VERSION "created by canmatrix"

NS_ :

BS_:

BU_:

BO_ 16751425 CommandModeControlAPU2: 9 Vector__XXX
 SG_ Enable_command : 6|2@0+ (1,0) [0|3] "" Vector__XXX
 SG_ FaultClear_command : 4|2@0+ (1,0) [0|3] "" Vector__XXX
 SG_ MasterFollowerMode_command : 22|2@0+ (1,0) [0|3] "" Vector__XXX
 SG_ ForceRelayMX1_command : 38|2@0+ (1,0) [0|3] "" Vector__XXX
 SG_ ForceRelayMX2_command : 36|2@0+ (1,0) [0|3] "" Vector__XXX
 SG_ ForceRelayK1_Precharge_command : 34|2@0+ (1,0) [0|3] "" Vector__XXX
 SG_ ForceRelayRelayK2_DCRun_comand : 32|2@0+ (1,0) [0|3] "" Vector__XXX
 SG_ InvertHwEnable_command : 62|2@0+ (1,0) [0|3] "" Vector__XXX
 SG_ EnableUPSMode_command : 60|2@0+ (1,0) [0|3] "" Vector__XXX
 SG_ EnableSplitPhase_command : 58|2@0+ (1,0) [0|3] "" Vector__XXX
 SG_ PhaseRotation_command : 56|2@0+ (1,0) [0|3] "" Vector__XXX

BO_ 16755521 CommandModeControl: 9 Vector__XXX
 SG_ Enable_command : 6|2@0+ (1,0) [0|3] "" Vector__XXX
 SG_ FaultClear_command : 4|2@0+ (1,0) [0|3] "" Vector__XXX
 SG_ MasterFollowerMode_command : 22|2@0+ (1,0) [0|3] "" Vector__XXX
 SG_ ForceRelayMX1_command : 38|2@0+ (1,0) [0|3] "" Vector__XXX
 SG_ ForceRelayMX2_command : 36|2@0+ (1,0) [0|3] "" Vector__XXX
 SG_ ForceRelayK1_Precharge_command : 34|2@0+ (1,0) [0|3] "" Vector__XXX
 SG_ ForceRelayRelayK2_DCRun_comand : 32|2@0+ (1,0) [0|3] "" Vector__XXX
 SG_ InvertHwEnable_command : 62|2@0+ (1,0) [0|3] "" Vector__XXX
 SG_ EnableUPSMode_command : 60|2@0+ (1,0) [0|3] "" Vector__XXX
 SG_ EnableSplitPhase_command : 58|2@0+ (1,0) [0|3] "" Vector__XXX
 SG_ PhaseRotation_command : 56|2@0+ (1,0) [0|3] "" Vector__XXX

BO_ 218078273 CommandPowerAPU2: 9 Vector__XXX
 SG_ RealPower_command : 0|32@0+ (1,-90000) [-90000|90000] "W" Vector__XXX
 SG_ ReactivePower_command : 32|32@0+ (1,-90000) [-90000|90000] "VA" Vector__XXX

BO_ 218078785 CommandVFAPU2: 8 Vector__XXX
 SG_ Voltage_command : 0|16@0+ (0.1,10) [10|500] "Vrms" Vector__XXX
 SG_ Frequency_command : 16|16@0+ (0.1,45) [45|65] "Hz" Vector__XXX

BO_ 218081857 CommandSetNVParam: 9 Vector__XXX
 SG_ CommandSetNVParam_MUX M : 0|16@0+ (1,0) [0|65535] "" Vector__XXX
 SG_ ThermalOverload m6 : 22|2@0+ (1,0) [0|3] "" Vector__XXX
 SG_ Dummy m0 : 16|16@0+ (1,0) [0|65535] "" Vector__XXX
 SG_ FreqHi0 m3 : 16|16@0+ (0.1,40) [40|70] "Hz" Vector__XXX
 SG_ FreqVeryLo0 m4 : 16|16@0+ (1,160) [160|160] "ms" Vector__XXX
 SG_ K2Open m9 : 16|16@0+ (1,0) [0|2000] "ms" Vector__XXX
 SG_ MX1Open m7 : 16|16@0+ (1,0) [0|5000] "ms" Vector__XXX
 SG_ MX2Close m8 : 16|16@0+ (1,0) [0|2000] "ms" Vector__XXX
 SG_ NodeID m5 : 16|8@0+ (1,0) [0|247] "" Vector__XXX
 SG_ VOver120 m2 : 16|16@0+ (1,1) [1|30000] "" Vector__XXX
 SG_ VUnder50pct m1 : 16|16@0+ (1,1) [1|30000] "ms" Vector__XXX
 SG_ SA_Mask m5 : 24|8@0+ (1,0) [0|255] "" Vector__XXX
 SG_ Baudrate m5 : 32|4@0+ (1,0) [0|15] "" Vector__XXX
 SG_ FreqLo m4 : 32|16@0+ (1,1) [1|30000] "ms" Vector__XXX
 SG_ K1Open m8 : 32|16@0+ (1,0) [0|2000] "ms" Vector__XXX
 SG_ K2Close m9 : 32|16@0+ (1,0) [0|2000] "ms" Vector__XXX
 SG_ MX1Close m7 : 32|16@0+ (1,0) [0|2000] "ms" Vector__XXX
 SG_ V50to88pct m1 : 32|16@0+ (1,1) [1|30000] "ms" Vector__XXX
 SG_ FreqHi1 m4 : 48|16@0+ (1,160) [160|160] "ms" Vector__XXX
 SG_ FreqVeryLo1 m3 : 48|16@0+ (0.1,40) [40|70] "Hz" Vector__XXX
 SG_ K1Close m8 : 48|16@0+ (1,0) [0|2000] "ms" Vector__XXX
 SG_ MX2Open m7 : 48|16@0+ (1,0) [0|65535] "ms" Vector__XXX
 SG_ V110to120pct m1 : 48|16@0+ (1,1) [1|30000] "ms" Vector__XXX

BO_ 218082369 CommandPower: 9 Vector__XXX
 SG_ RealPower_command : 0|32@0+ (1,-90000) [-90000|90000] "W" Vector__XXX
 SG_ ReactivePower_command : 32|32@0+ (1,-90000) [-90000|90000] "VA" Vector__XXX

BO_ 218082881 CommandVF: 8 Vector__XXX
 SG_ Voltage_command : 0|16@0+ (0.1,10) [10|500] "Vrms" Vector__XXX
 SG_ Frequency_command : 16|16@0+ (0.1,45) [45|65] "Hz" Vector__XXX

BO_ 218083137 CommandFactoryControl: 9 Vector__XXX
 SG_ WriteSerialNumber : 6|2@0+ (1,0) [0|3] "" Vector__XXX
 SG_ FactoryAccess : 16|16@0+ (1,0) [0|65535] "" Vector__XXX
 SG_ SerialNumber : 32|32@0+ (1,0) [0|4294967295] "" Vector__XXX

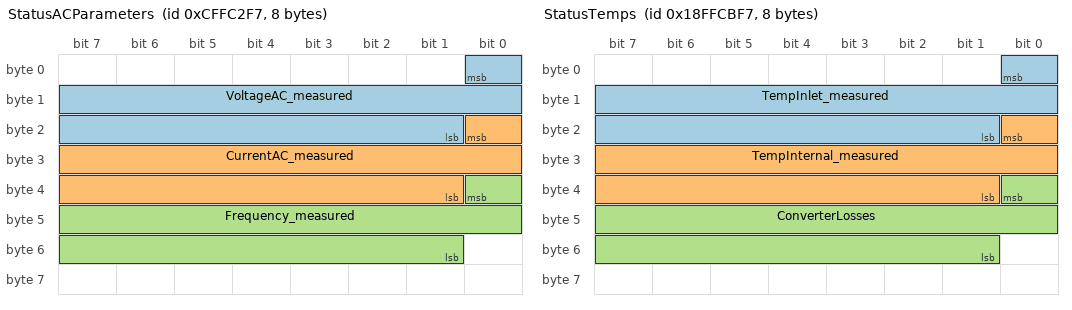
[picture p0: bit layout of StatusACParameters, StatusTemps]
BO_ 218088183 StatusACParameters: 8 Vector__XXX
 SG_ VoltageAC_measured : 0|16@0+ (0.1,0) [0|65535] "V" Vector__XXX
 SG_ CurrentAC_measured : 16|16@0+ (1,0) [0|65535] "A" Vector__XXX
 SG_ Frequency_measured : 32|16@0+ (0.1,0) [0|65535] "Hz" Vector__XXX

BO_ 218088439 StatusBits: 8 Vector__XXX
 SG_ State_status : 4|4@0+ (1,0) [0|15] "" Vector__XXX
 SG_ Enable_echo : 2|2@0+ (1,0) [0|3] "" Vector__XXX
 SG_ FaultClr_echo : 0|2@0+ (1,0) [0|3] "" Vector__XXX
 SG_ HardwareEnable_status : 14|2@0+ (1,0) [0|3] "" Vector__XXX
 SG_ PowerAvailAC_status : 12|2@0+ (1,0) [0|3] "" Vector__XXX
 SG_ PowerAvailDC_status : 10|2@0+ (1,0) [0|3] "" Vector__XXX
 SG_ PowerCircuitEnabled_status : 8|2@0+ (1,0) [0|3] "" Vector__XXX
 SG_ MX1Permissive_status : 22|2@0+ (1,0) [0|3] "" Vector__XXX
 SG_ MX2Permissive_status : 20|2@0+ (1,0) [0|3] "" Vector__XXX
 SG_ K1PrechargePermissive_status : 18|2@0+ (1,0) [0|3] "" Vector__XXX
 SG_ K2DCRunPermissive_status : 16|2@0+ (1,0) [0|3] "" Vector__XXX
 SG_ MessageValidModeControl_status : 30|2@0+ (1,0) [0|3] "" Vector__XXX
 SG_ MessageValidPowerCMD_status : 28|2@0+ (1,0) [0|3] "" Vector__XXX
 SG_ MessageValidVF_status : 26|2@0+ (1,0) [0|3] "" Vector__XXX
 SG_ CANbus_status : 24|2@0+ (1,0) [0|3] "" Vector__XXX
 SG_ EnableUPSMode_echo : 38|2@0+ (1,0) [0|3] "" Vector__XXX
 SG_ EnableSplitPhase_echo : 36|2@0+ (1,0) [0|3] "" Vector__XXX
 SG_ PhaseRotation_status : 34|2@0+ (1,0) [0|3] "" Vector__XXX
 SG_ LineVoltageDetected_status : 32|2@0+ (1,0) [0|3] "" Vector__XXX
 SG_ PhaseRotation_echo : 46|2@0+ (1,0) [0|3] "" Vector__XXX

BO_ 218089719 StatusFaults: 8 Vector__XXX
 SG_ GeneralFault_status : 6|2@0+ (1,0) [0|3] "" Vector__XXX
 SG_ OvercurrentAC_status : 4|2@0+ (1,0) [0|3] "" Vector__XXX
 SG_ LossOfAC_status : 2|2@0+ (1,0) [0|3] "" Vector__XXX
 SG_ OvercurrentDC_status : 0|2@0+ (1,0) [0|3] "" Vector__XXX
 SG_ OvervoltageDC_status : 14|2@0+ (1,0) [0|3] "" Vector__XXX
 SG_ UndervoltageDC_status : 12|2@0+ (1,0) [0|3] "" Vector__XXX
 SG_ OvertempInternal_status : 10|2@0+ (1,0) [0|3] "" Vector__XXX
 SG_ OvertempPowerDevice_status : 8|2@0+ (1,0) [0|3] "" Vector__XXX
 SG_ ControlHardwareFail_status : 20|4@0+ (1,0) [0|15] "" Vector__XXX
 SG_ LossValidControlMessage_status : 16|4@0+ (1,0) [0|15] "" Vector__XXX
 SG_ EStopShutdown_status : 30|2@0+ (1,0) [0|3] "" Vector__XXX
 SG_ IllegalTransition_status : 28|2@0+ (1,0) [0|3] "" Vector__XXX
 SG_ InvalidEEHeader_status : 26|2@0+ (1,0) [0|3] "" Vector__XXX
 SG_ InvalidEESection_status : 24|2@0+ (1,0) [0|3] "" Vector__XXX
 SG_ ThermalOverload : 38|2@0+ (1,0) [0|3] "" Vector__XXX
 SG_ BridgeBFault_status : 45|3@0+ (1,0) [0|7] "" Vector__XXX
 SG_ BridgeBVoltageOk_status : 44|1@0+ (1,0) [0|1] "" Vector__XXX
 SG_ BridgeAFault_status : 61|3@0+ (1,0) [0|7] "" Vector__XXX
 SG_ BridgeAVoltageOk_status : 60|1@0+ (1,0) [0|1] "" Vector__XXX

BO_ 218090230 MasterMeasuredPower: 9 Vector__XXX
 SG_ RealPower_measured : 0|32@0+ (1,0) [0|4294967295] "W" Vector__XXX
 SG_ ReactivePower_measured : 32|32@0+ (1,0) [0|4294967295] "VA" Vector__XXX

BO_ 218090231 StatusMeasuredPower: 9 Vector__XXX
 SG_ RealPower_measured : 0|32@0+ (1,0) [0|4294967295] "W" Vector__XXX
 SG_ ReactivePower_measured : 32|32@0+ (1,0) [0|4294967295] "VA" Vector__XXX

BO_ 419415287 StatusCommandedPower: 9 Vector__XXX
 SG_ RealPower_echo : 0|32@0+ (1,0) [0|4294967295] "W" Vector__XXX
 SG_ ReactivePower_echo : 32|32@0+ (1,0) [0|4294967295] "VA" Vector__XXX

BO_ 419416567 StatusCommandVF: 8 Vector__XXX
 SG_ Voltage_echo : 0|16@0+ (0.1,0) [0|65535] "Vrms" Vector__XXX
 SG_ Frequency_echo : 16|16@0+ (0.1,0) [0|65535] "Hz" Vector__XXX

BO_ 419417079 StatusTemps: 8 Vector__XXX
 SG_ TempInlet_measured : 0|16@0+ (0.1,0) [0|65535] "C" Vector__XXX
 SG_ TempInternal_measured : 16|16@0+ (0.1,0) [0|65535] "C" Vector__XXX
 SG_ ConverterLosses : 32|16@0+ (1,0) [0|65535] "W" Vector__XXX

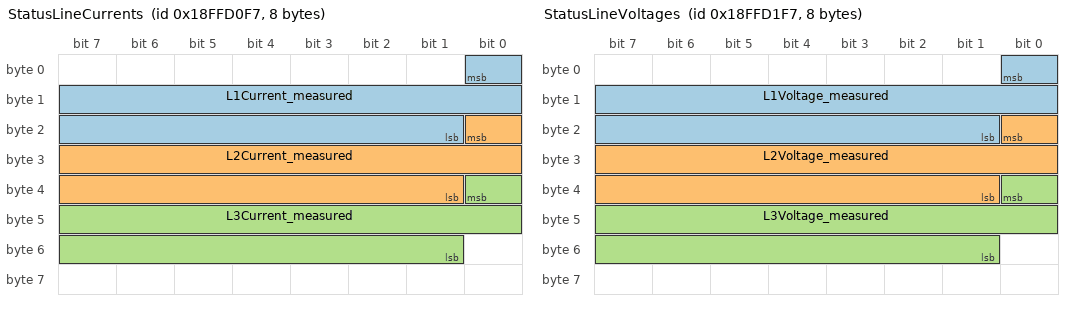
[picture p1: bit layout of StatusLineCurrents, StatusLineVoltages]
BO_ 419418359 StatusLineCurrents: 8 Vector__XXX
 SG_ L1Current_measured : 0|16@0+ (1,0) [0|65535] "A" Vector__XXX
 SG_ L2Current_measured : 16|16@0+ (1,0) [0|65535] "A" Vector__XXX
 SG_ L3Current_measured : 32|16@0+ (1,0) [0|65535] "A" Vector__XXX

BO_ 419418615 StatusLineVoltages: 8 Vector__XXX
 SG_ L1Voltage_measured : 0|16@0+ (0.1,0) [0|65535] "Vrms" Vector__XXX
 SG_ L2Voltage_measured : 16|16@0+ (0.1,0) [0|65535] "Vrms" Vector__XXX
 SG_ L3Voltage_measured : 32|16@0+ (0.1,0) [0|65535] "Vrms" Vector__XXX

BO_ 486517239 StatusNVParam: 9 Vector__XXX
 SG_ StatusNVParam_MUX M : 0|16@0+ (1,0) [0|65535] "" Vector__XXX
 SG_ StatusThermalOverload m6 : 22|2@0+ (1,0) [0|3] "" Vector__XXX
 SG_ Dummy m0 : 16|16@0+ (1,5) [5|10] "" Vector__XXX
 SG_ FreqHi0 m3 : 16|16@0+ (0.1,40) [40|70] "Hz" Vector__XXX
 SG_ FreqVeryLo0 m4 : 16|16@0+ (1,160) [160|160] "ms" Vector__XXX
 SG_ StatusK2Open m9 : 16|16@0+ (1,0) [0|2000] "ms" Vector__XXX
 SG_ StatusMX1Open m7 : 16|16@0+ (1,0) [0|5000] "ms" Vector__XXX
 SG_ StatusMX2Close m8 : 16|16@0+ (1,0) [0|2000] "ms" Vector__XXX
 SG_ StatusNodeID m5 : 16|8@0+ (1,0) [0|247] "" Vector__XXX
 SG_ VOver120 m2 : 16|16@0+ (1,1) [1|30000] "" Vector__XXX
 SG_ VUnder50pct m1 : 16|16@0+ (1,1) [1|30000] "ms" Vector__XXX
 SG_ StatusSA_Mask m5 : 24|8@0+ (1,0) [0|255] "" Vector__XXX
 SG_ FreqLo m4 : 32|16@0+ (1,1) [1|30000] "ms" Vector__XXX
 SG_ StatusBaudrate m5 : 32|4@0+ (1,0) [0|15] "" Vector__XXX
 SG_ StatusK1Open m8 : 32|16@0+ (1,0) [0|2000] "ms" Vector__XXX
 SG_ StatusK2Close m9 : 32|16@0+ (1,0) [0|2000] "ms" Vector__XXX
 SG_ StatusMX1Close m7 : 32|16@0+ (1,0) [0|2000] "ms" Vector__XXX
 SG_ V50to88pct m1 : 32|16@0+ (1,1) [1|30000] "ms" Vector__XXX
 SG_ FreqHi1 m4 : 48|16@0+ (1,160) [160|160] "ms" Vector__XXX
 SG_ FreqVeryLo1 m3 : 48|16@0+ (0.1,40) [40|70] "Hz" Vector__XXX
 SG_ StatusK1Close m8 : 48|16@0+ (1,0) [0|2000] "ms" Vector__XXX
 SG_ StatusMX2Open m7 : 48|16@0+ (1,0) [0|65535] "ms" Vector__XXX
 SG_ V110to120pct m1 : 48|16@0+ (1,1) [1|30000] "ms" Vector__XXX

BO_ 486523383 softwareRev: 9 Vector__XXX
 SG_ ControlSwRev : 0|16@0+ (1,0) [0|65535] "" Vector__XXX
 SG_ InterfaceRev : 16|16@0+ (1,0) [0|65535] "" Vector__XXX
 SG_ BuildTime : 32|32@0+ (1,0) [0|4294967295] "" Vector__XXX

BO_ 486524407 StatusControlVoltage: 9 Vector__XXX
 SG_ v5p0_Supply : 0|16@0+ (0.01,0) [0|65535] "V" Vector__XXX
 SG_ v3p3_Supply : 16|16@0+ (0.01,0) [0|65535] "V" Vector__XXX
 SG_ v24_Supply : 32|16@0+ (0.01,0) [0|65535] "V" Vector__XXX
 SG_ v15_Supply : 48|16@0+ (0.01,0) [0|65535] "V" Vector__XXX

BO_ 486524663 StatusControlVolts2: 9 Vector__XXX
 SG_ n15V_Supply : 0|16@0+ (0.01,0) [0|65535] "V" Vector__XXX
 SG_ DiodeTemperature : 32|16@0+ (1,0) [0|65535] "C" Vector__XXX
 SG_ IGBTTemperature : 48|16@0+ (1,0) [0|65535] "C" Vector__XXX

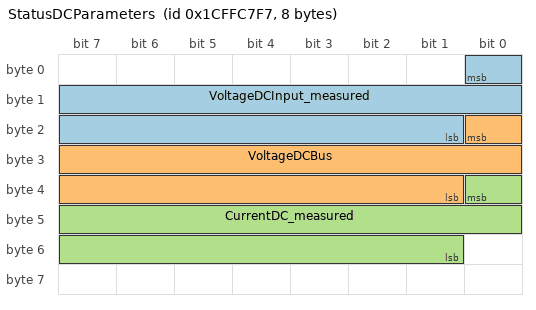
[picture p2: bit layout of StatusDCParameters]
BO_ 486524919 StatusDCParameters: 8 Vector__XXX
 SG_ VoltageDCInput_measured : 0|16@0+ (1,0) [0|65535] "V" Vector__XXX
 SG_ VoltageDCBus : 16|16@0+ (1,0) [0|65535] "V" Vector__XXX
 SG_ CurrentDC_measured : 32|16@0+ (1,0) [0|65535] "A" Vector__XXX

BO_ 486526199 serialNumber: 8 Vector__XXX
 SG_ SerialNumber : 0|32@0+ (1,0) [0|4294967295] "" Vector__XXX

BO_ 486526455 softwareRevHash: 8 Vector__XXX
 SG_ Hash : 0|28@0+ (1,0) [0|268435455] "" Vector__XXX

BA_DEF_ BO_ "GenMsgCycleTime" INT 0 65535;
BA_DEF_ BO_ "GenMsgSendType" ENU;
BA_DEF_ BO_ "VFrameFormat" ENUM "StandardCAN","ExtendedCAN","StandardCAN_FD","ExtendedCAN_FD","J1939PG";
BA_DEF_ "BusType" STRING;

BA_ "BusType" "CAN FD";

BA_ "GenMsgCycleTime" BO_ 16751425 0;
BA_ "GenMsgSendType" BO_ 16751425 "";
BA_ "VFrameFormat" BO_ 16751425 2;
BA_ "GenMsgCycleTime" BO_ 16755521 0;
BA_ "GenMsgSendType" BO_ 16755521 "";
BA_ "VFrameFormat" BO_ 16755521 2;
BA_ "GenMsgCycleTime" BO_ 218078273 0;
BA_ "GenMsgSendType" BO_ 218078273 "";
BA_ "VFrameFormat" BO_ 218078273 2;
BA_ "GenMsgCycleTime" BO_ 218078785 0;
BA_ "GenMsgSendType" BO_ 218078785 "";
BA_ "VFrameFormat" BO_ 218078785 0;
BA_ "GenMsgCycleTime" BO_ 218081857 0;
BA_ "GenMsgSendType" BO_ 218081857 "";
BA_ "VFrameFormat" BO_ 218081857 2;
BA_ "GenMsgCycleTime" BO_ 218082369 0;
BA_ "GenMsgSendType" BO_ 218082369 "";
BA_ "VFrameFormat" BO_ 218082369 2;
BA_ "GenMsgCycleTime" BO_ 218082881 0;
BA_ "GenMsgSendType" BO_ 218082881 "";
BA_ "VFrameFormat" BO_ 218082881 0;
BA_ "GenMsgCycleTime" BO_ 218083137 0;
BA_ "GenMsgSendType" BO_ 218083137 "";
BA_ "VFrameFormat" BO_ 218083137 2;
BA_ "GenMsgCycleTime" BO_ 218088183 100;
BA_ "GenMsgSendType" BO_ 218088183 "";
BA_ "VFrameFormat" BO_ 218088183 0;
BA_ "GenMsgCycleTime" BO_ 218088439 100;
BA_ "GenMsgSendType" BO_ 218088439 "";
BA_ "VFrameFormat" BO_ 218088439 0;
BA_ "GenMsgCycleTime" BO_ 218089719 100;
BA_ "GenMsgSendType" BO_ 218089719 "";
BA_ "VFrameFormat" BO_ 218089719 0;
BA_ "GenMsgCycleTime" BO_ 218090230 0;
BA_ "GenMsgSendType" BO_ 218090230 "";
BA_ "VFrameFormat" BO_ 218090230 2;
BA_ "GenMsgCycleTime" BO_ 218090231 100;
BA_ "GenMsgSendType" BO_ 218090231 "";
BA_ "VFrameFormat" BO_ 218090231 2;
BA_ "GenMsgCycleTime" BO_ 419415287 100;
BA_ "GenMsgSendType" BO_ 419415287 "";
BA_ "VFrameFormat" BO_ 419415287 2;
BA_ "GenMsgCycleTime" BO_ 419416567 100;
BA_ "GenMsgSendType" BO_ 419416567 "";
BA_ "VFrameFormat" BO_ 419416567 0;
BA_ "GenMsgCycleTime" BO_ 419417079 100;
BA_ "GenMsgSendType" BO_ 419417079 "";
BA_ "VFrameFormat" BO_ 419417079 0;
BA_ "GenMsgCycleTime" BO_ 419418359 100;
BA_ "GenMsgSendType" BO_ 419418359 "";
BA_ "VFrameFormat" BO_ 419418359 0;
BA_ "GenMsgCycleTime" BO_ 419418615 100;
BA_ "GenMsgSendType" BO_ 419418615 "";
BA_ "VFrameFormat" BO_ 419418615 0;
BA_ "GenMsgCycleTime" BO_ 486517239 0;
BA_ "GenMsgSendType" BO_ 486517239 "";
BA_ "VFrameFormat" BO_ 486517239 2;
BA_ "GenMsgCycleTime" BO_ 486523383 0;
BA_ "GenMsgSendType" BO_ 486523383 "";
BA_ "VFrameFormat" BO_ 486523383 2;
BA_ "GenMsgCycleTime" BO_ 486524407 100;
BA_ "GenMsgSendType" BO_ 486524407 "";
BA_ "VFrameFormat" BO_ 486524407 2;
BA_ "GenMsgCycleTime" BO_ 486524663 100;
BA_ "GenMsgSendType" BO_ 486524663 "";
BA_ "VFrameFormat" BO_ 486524663 2;
BA_ "GenMsgCycleTime" BO_ 486524919 100;
BA_ "GenMsgSendType" BO_ 486524919 "";
BA_ "VFrameFormat" BO_ 486524919 0;
BA_ "GenMsgCycleTime" BO_ 486526199 0;
BA_ "GenMsgSendType" BO_ 486526199 "";
BA_ "VFrameFormat" BO_ 486526199 0;
BA_ "GenMsgCycleTime" BO_ 486526455 0;
BA_ "GenMsgSendType" BO_ 486526455 "";
BA_ "VFrameFormat" BO_ 486526455 0;

VAL_ 16751425 Enable_command 0 "Disable" 1 "Enable" 2 "Error" 3 "N/A";
VAL_ 16751425 FaultClear_command 0 "Normal" 1 "Clear Faults" 2 "Error" 3 "N/A";
VAL_ 16751425 MasterFollowerMode_command 0 "Master" 1 "Follower" 2 "Error" 3 "N/A";
VAL_ 16751425 ForceRelayMX1_command 0 "Normal" 1 "Force On" 2 "Error" 3 "N/A";
VAL_ 16751425 ForceRelayMX2_command 0 "Normal" 1 "Force On" 2 "Error" 3 "N/A";
VAL_ 16751425 ForceRelayK1_Precharge_command 0 "Normal" 1 "Force On" 2 "Error" 3 "N/A";
VAL_ 16751425 ForceRelayRelayK2_DCRun_comand 0 "Normal" 1 "Force On" 2 "Error" 3 "N/A";
VAL_ 16751425 InvertHwEnable_command 0 "No invert" 1 "Invert" 2 "Error" 3 "N/A";
VAL_ 16751425 EnableUPSMode_command 0 "Disable" 1 "Enable" 2 "Error" 3 "N/A";
VAL_ 16751425 EnableSplitPhase_command 0 "Normal - Three Phase Mode" 1 "Enable Split Phase Mode" 2 "Error" 3 "N/A";
VAL_ 16751425 PhaseRotation_command 0 "Negative" 1 "Positive" 2 "Error" 3 "N/A";
VAL_ 16755521 Enable_command 0 "Disable" 1 "Enable" 2 "Error" 3 "N/A";
VAL_ 16755521 FaultClear_command 0 "Normal" 1 "Clear Faults" 2 "Error" 3 "N/A";
VAL_ 16755521 MasterFollowerMode_command 0 "Master" 1 "Follower" 2 "Error" 3 "N/A";
VAL_ 16755521 ForceRelayMX1_command 0 "Normal" 1 "Force On" 2 "Error" 3 "N/A";
VAL_ 16755521 ForceRelayMX2_command 0 "Normal" 1 "Force On" 2 "Error" 3 "N/A";
VAL_ 16755521 ForceRelayK1_Precharge_command 0 "Normal" 1 "Force On" 2 "Error" 3 "N/A";
VAL_ 16755521 ForceRelayRelayK2_DCRun_comand 0 "Normal" 1 "Force On" 2 "Error" 3 "N/A";
VAL_ 16755521 InvertHwEnable_command 0 "No invert" 1 "Invert" 2 "Error" 3 "N/A";
VAL_ 16755521 EnableUPSMode_command 0 "Disable" 1 "Enable" 2 "Error" 3 "N/A";
VAL_ 16755521 EnableSplitPhase_command 0 "Normal - Three Phase Mode" 1 "Enable Split Phase Mode" 2 "Error" 3 "N/A";
VAL_ 16755521 PhaseRotation_command 0 "Negative" 1 "Positive" 2 "Error" 3 "N/A";
VAL_ 218081857 CommandSetNVParam_MUX 0 "Param0" 1 "LVM_ClearingTimes1" 2 "LVM_ClearingTimes2" 3 "LFM_Limits" 4 "LFM_ClearingTimes" 5 "J1939_Interface" 6 "Fault_Config" 7 "ContactorDelays1" 8 "ContactorDelays2" 9 "ContactorDelays3";
VAL_ 218081857 ThermalOverload 0 "Warning" 1 "Fault" 2 "Error" 3 "N/A";
VAL_ 218081857 Baudrate 0 "125K" 1 "250K" 2 "500K" 3 "1M";
VAL_ 218083137 WriteSerialNumber 0 "Disable" 1 "Enable" 2 "Error" 3 "N/A";
VAL_ 218088439 State_status 0 "Power On Reset" 1 "Ready" 2 "Following" 3 "Fault" 4 "Forming" 5 "N/A" 6 "N/A" 7 "N/A" 8 "N/A" 9 "N/A" 10 "N/A" 11 "N/A" 12 "N/A" 13 "N/A" 14 "N/A" 15 "N/A";
VAL_ 218088439 Enable_echo 0 "Disable" 1 "Enable" 2 "Error" 3 "N/A";
VAL_ 218088439 FaultClr_echo 0 "Normal" 1 "Clear Faults" 2 "Error" 3 "N/A";
VAL_ 218088439 HardwareEnable_status 0 "Not Active" 1 "Active" 2 "Error" 3 "N/A";
VAL_ 218088439 PowerAvailAC_status 0 "None" 1 "Available" 2 "Error" 3 "N/A";
VAL_ 218088439 PowerAvailDC_status 0 "None" 1 "Available" 2 "Error" 3 "N/A";
VAL_ 218088439 PowerCircuitEnabled_status 0 "Disabled" 1 "Enabled" 2 "Error" 3 "N/A";
VAL_ 218088439 MX1Permissive_status 0 "Open" 1 "Closed" 2 "Error" 3 "N/A";
VAL_ 218088439 MX2Permissive_status 0 "Open" 1 "Closed" 2 "Error" 3 "N/A";
VAL_ 218088439 K1PrechargePermissive_status 0 "Open" 1 "Closed" 2 "Error" 3 "N/A";
VAL_ 218088439 K2DCRunPermissive_status 0 "Open" 1 "Closed" 2 "Error" 3 "N/A";
VAL_ 218088439 MessageValidModeControl_status 0 "Invalid" 1 "Valid" 2 "Error" 3 "N/A";
VAL_ 218088439 MessageValidPowerCMD_status 0 "Invalid" 1 "Valid" 2 "Error" 3 "N/A";
VAL_ 218088439 MessageValidVF_status 0 "Invalid" 1 "Valid" 2 "Error" 3 "N/A";
VAL_ 218088439 CANbus_status 0 "Normal" 1 "Warning" 3 "ErrorPassive" 4 "N/A";
VAL_ 218088439 EnableUPSMode_echo 0 "Disable" 1 "Enable" 2 "Error" 3 "N/A";
VAL_ 218088439 EnableSplitPhase_echo 0 "Normal - Three Phase Mode" 1 "Enable Split Phase Mode" 2 "Error" 3 "N/A";
VAL_ 218088439 PhaseRotation_status 0 "Negative" 1 "Positive" 2 "Error" 3 "N/A";
VAL_ 218088439 LineVoltageDetected_status 0 "No_Voltage" 1 "Voltage_Detected" 2 "Error" 3 "N/A";
VAL_ 218088439 PhaseRotation_echo 0 "Negative" 1 "Positive" 2 "Error" 3 "N/A";
VAL_ 218089719 GeneralFault_status 0 "Normal" 1 "Fault Active" 2 "Error" 3 "N/A";
VAL_ 218089719 OvercurrentAC_status 0 "Normal" 1 "Fault Active" 2 "Error" 3 "N/A";
VAL_ 218089719 LossOfAC_status 0 "Normal" 1 "Fault Active" 2 "Error" 3 "N/A";
VAL_ 218089719 OvercurrentDC_status 0 "Normal" 1 "Fault Active" 2 "Error" 3 "N/A";
VAL_ 218089719 OvervoltageDC_status 0 "Normal" 1 "Fault Active" 2 "Error" 3 "N/A";
VAL_ 218089719 UndervoltageDC_status 0 "Normal" 1 "Fault Active" 2 "Error" 3 "N/A";
VAL_ 218089719 OvertempInternal_status 0 "Normal" 1 "Fault Active" 2 "Error" 3 "N/A";
VAL_ 218089719 OvertempPowerDevice_status 0 "Normal" 1 "Fault Active" 2 "Error" 3 "N/A";
VAL_ 218089719 ControlHardwareFail_status 0 "Normal" 1 "Fault Active" 2 "Error" 3 "N/A";
VAL_ 218089719 LossValidControlMessage_status 0 "Normal" 1 "Fault Active" 2 "Error" 3 "N/A";
VAL_ 218089719 EStopShutdown_status 0 "Normal" 1 "Fault Active" 2 "Error" 3 "N/A";
VAL_ 218089719 IllegalTransition_status 0 "Normal" 1 "Fault Active" 2 "Error" 3 "N/A";
VAL_ 218089719 InvalidEEHeader_status 0 "Normal" 1 "Fault Active" 2 "Error" 3 "N/A";
VAL_ 218089719 InvalidEESection_status 0 "Normal" 1 "Fault Active" 2 "Error" 3 "N/A";
VAL_ 218089719 ThermalOverload 0 "Normal" 1 "Fault Active" 2 "Error" 3 "N/A";
VAL_ 218089719 BridgeBFault_status 0 "Normal" 1 "FLT_A" 2 "N/A" 3 "FLT_C" 4 "OverVoltage" 5 "FLT_B" 6 "Overcurrent" 7 "5V";
VAL_ 218089719 BridgeBVoltageOk_status 0 "Normal" 1 "Fault Active" 2 "Error" 3 "N/A";
VAL_ 218089719 BridgeAFault_status 0 "Normal" 1 "FLT_A" 2 "N/A" 3 "FLT_C" 4 "OverVoltage" 5 "FLT_B" 6 "Overcurrent" 7 "5V";
VAL_ 218089719 BridgeAVoltageOk_status 0 "Normal" 1 "Fault Active" 2 "Error" 3 "N/A";
VAL_ 486517239 StatusNVParam_MUX 0 "ActParam0" 1 "ActLVM_ClearingTimes1" 2 "ActLVM_ClearingTimes2" 3 "ActLFM_Limits" 4 "ActLFM_ClearingTimes" 5 "StatusJ1939_Interface" 6 "StatusFault_Config" 7 "StatusContactorDelays1" 8 "StatusContactorDelays2" 9 "StatusContactorDelays3";
VAL_ 486517239 StatusThermalOverload 0 "Warning" 1 "Fault" 2 "Error" 3 "N/A";
VAL_ 486517239 StatusBaudrate 0 "125K" 1 "250K" 2 "500K" 3 "1M";
